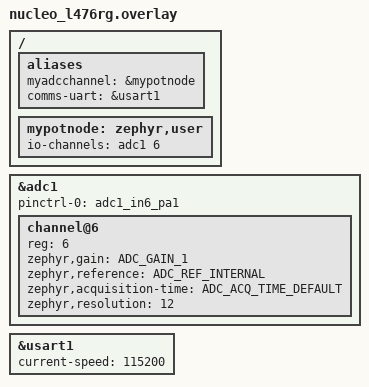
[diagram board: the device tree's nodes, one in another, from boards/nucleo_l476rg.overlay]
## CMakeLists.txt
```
# SPDX-License-Identifier: Apache-2.0

cmake_minimum_required(VERSION 3.20.0)
find_package(Zephyr REQUIRED HINTS $ENV{ZEPHYR_BASE})
project(
    solid-state-anemometer
    VERSION 1.0
    LANGUAGES C CXX
)

zephyr_include_directories(include)

target_sources(app PRIVATE src/main.cpp)

add_subdirectory(src/comms)
add_subdirectory(src/adc)
#add_subdirectory(src/calculations)
```

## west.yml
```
manifest:
  remotes:
    - name: zephyrproject-rtos
      url-base: https://github.com/zephyrproject-rtos

  projects:
    # Imports the official Zephyr OS
    - name: zephyr
      remote: zephyrproject-rtos
      revision: v4.3.0
      import: true
      path: zephyr

  self:
    path: app
```

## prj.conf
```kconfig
CONFIG_CPP=y
CONFIG_STD_CPP17=y

CONFIG_GPIO=y
CONFIG_ADC=y
CONFIG_SERIAL=y
```

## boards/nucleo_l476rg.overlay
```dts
/ {
	aliases {
		myadcchannel = &mypotnode;
		comms-uart = &usart1;
	};

	mypotnode: zephyr,user {
		/* adjust channel number according to pinmux in board.dts */
		//status = "enabled";
		io-channels = <&adc1 6>;
	};
};

&adc1 {
	#address-cells = <1>;
	#size-cells = <0>;
	status = "okay";
	pinctrl-0 = <&adc1_in6_pa1>;

	channel@6 {
		reg = <6>;
		zephyr,gain = "ADC_GAIN_1";
		zephyr,reference = "ADC_REF_INTERNAL";
		zephyr,acquisition-time = <ADC_ACQ_TIME_DEFAULT>;
		zephyr,resolution = <12>;
	};
};

/* This enables USART1 on PA9/PA10 used for external comms */
&usart1 {
    status = "okay";
    current-speed = <115200>;
};
```

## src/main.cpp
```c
#include <comms_thread.hpp>
#include <adc_thread.hpp>

#include <zephyr/drivers/gpio.h>
#include <zephyr/drivers/uart.h>
#include <zephyr/drivers/adc.h>
#include <zephyr/kernel.h>

// Device tree setup
#define LED0_NODE DT_ALIAS(led0)
#define COMMS_UART DT_ALIAS(comms_uart)
static const struct gpio_dt_spec led = GPIO_DT_SPEC_GET(LED0_NODE, gpios);
const struct device* external_uart = DEVICE_DT_GET(COMMS_UART);
static const struct adc_dt_spec potentiometer = ADC_DT_SPEC_GET(DT_PATH(zephyr_user));

// Message queue setup between threads
// (10 items, 2 bytes each, aligned to 4-byte boundaries)
K_MSGQ_DEFINE(raw_adc_queue, sizeof(uint16_t), 10, 4);
K_MSGQ_DEFINE(calculated_data_queue, sizeof(uint16_t), 10, 4);

int main(void)
{
	if (!gpio_is_ready_dt(&led))
    {
		return 0;
	}
	if(gpio_pin_configure_dt(&led, GPIO_OUTPUT_ACTIVE) < 0)
	{
		return 0;
	}

	if(!device_is_ready(external_uart))
	{
		printk("UART device not ready\n");
		return 0;
	}
	if(!adc_is_ready_dt(&potentiometer))
	{
		printk("Potentiometer ADC device not ready\n");
        return 0;
    }
	
	comms::comms_thread_init(external_uart);
	adc::adc_thread_init(&potentiometer);

    bool led_state = false;
    while(1)
    {
        if(gpio_pin_set_dt(&led, led_state) < 0)
		{
			printk("Error: Could not toggle pin\n");
		}
        led_state = !led_state;
        k_msleep(1000);
    }
}
```

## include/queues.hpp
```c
#pragma once
#include <zephyr/kernel.h>

// Declare that these queues exist globally
extern struct k_msgq raw_adc_queue;
extern struct k_msgq calculated_data_queue;
```
